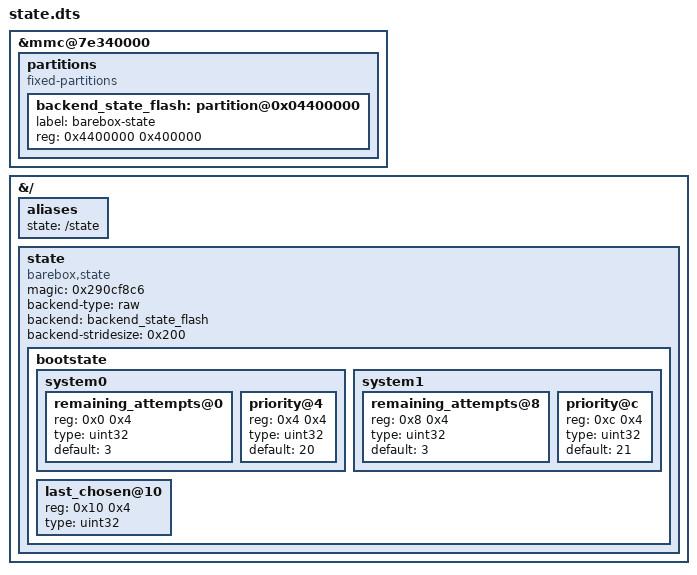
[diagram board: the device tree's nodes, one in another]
/* SPDX-License-Identifier: GPL-2.0-only */

/dts-v1/;
/plugin/;

&mmc@7e340000 {
	partitions {
		compatible = "fixed-partitions";
		#address-cells = <1>;
		#size-cells = <1>;

		backend_state_flash: partition@0x04400000 {
			label = "barebox-state";
			reg = <0x4400000 0x400000>;
		};
	};
};

&{/} {
	aliases {
		state = "/state";
	};

	state {
		#address-cells = <1>;
		#size-cells = <1>;
		compatible = "barebox,state";
		magic = <0x290cf8c6>;
		backend-type = "raw";
		backend = < &backend_state_flash >;
		backend-stridesize = <0x200>;

		bootstate {
			#address-cells = <1>;
			#size-cells = <1>;

			system0 {
				#address-cells = <1>;
				#size-cells = <1>;

				remaining_attempts@0 {
					reg = <0x0 0x4>;
					type = "uint32";
					default = <3>;
				};

				priority@4 {
					reg = <0x4 0x4>;
					type = "uint32";
					default = <20>;
				};
			};

			system1 {
				#address-cells = <1>;
				#size-cells = <1>;

				remaining_attempts@8 {
					reg = <0x8 0x4>;
					type = "uint32";
					default = <3>;
				};

				priority@c {
					reg = <0xc 0x4>;
					type = "uint32";
					default = <21>;
				};
			};

			last_chosen@10 {
				reg = <0x10 0x4>;
				type = "uint32";
			};
		};
	};
};
